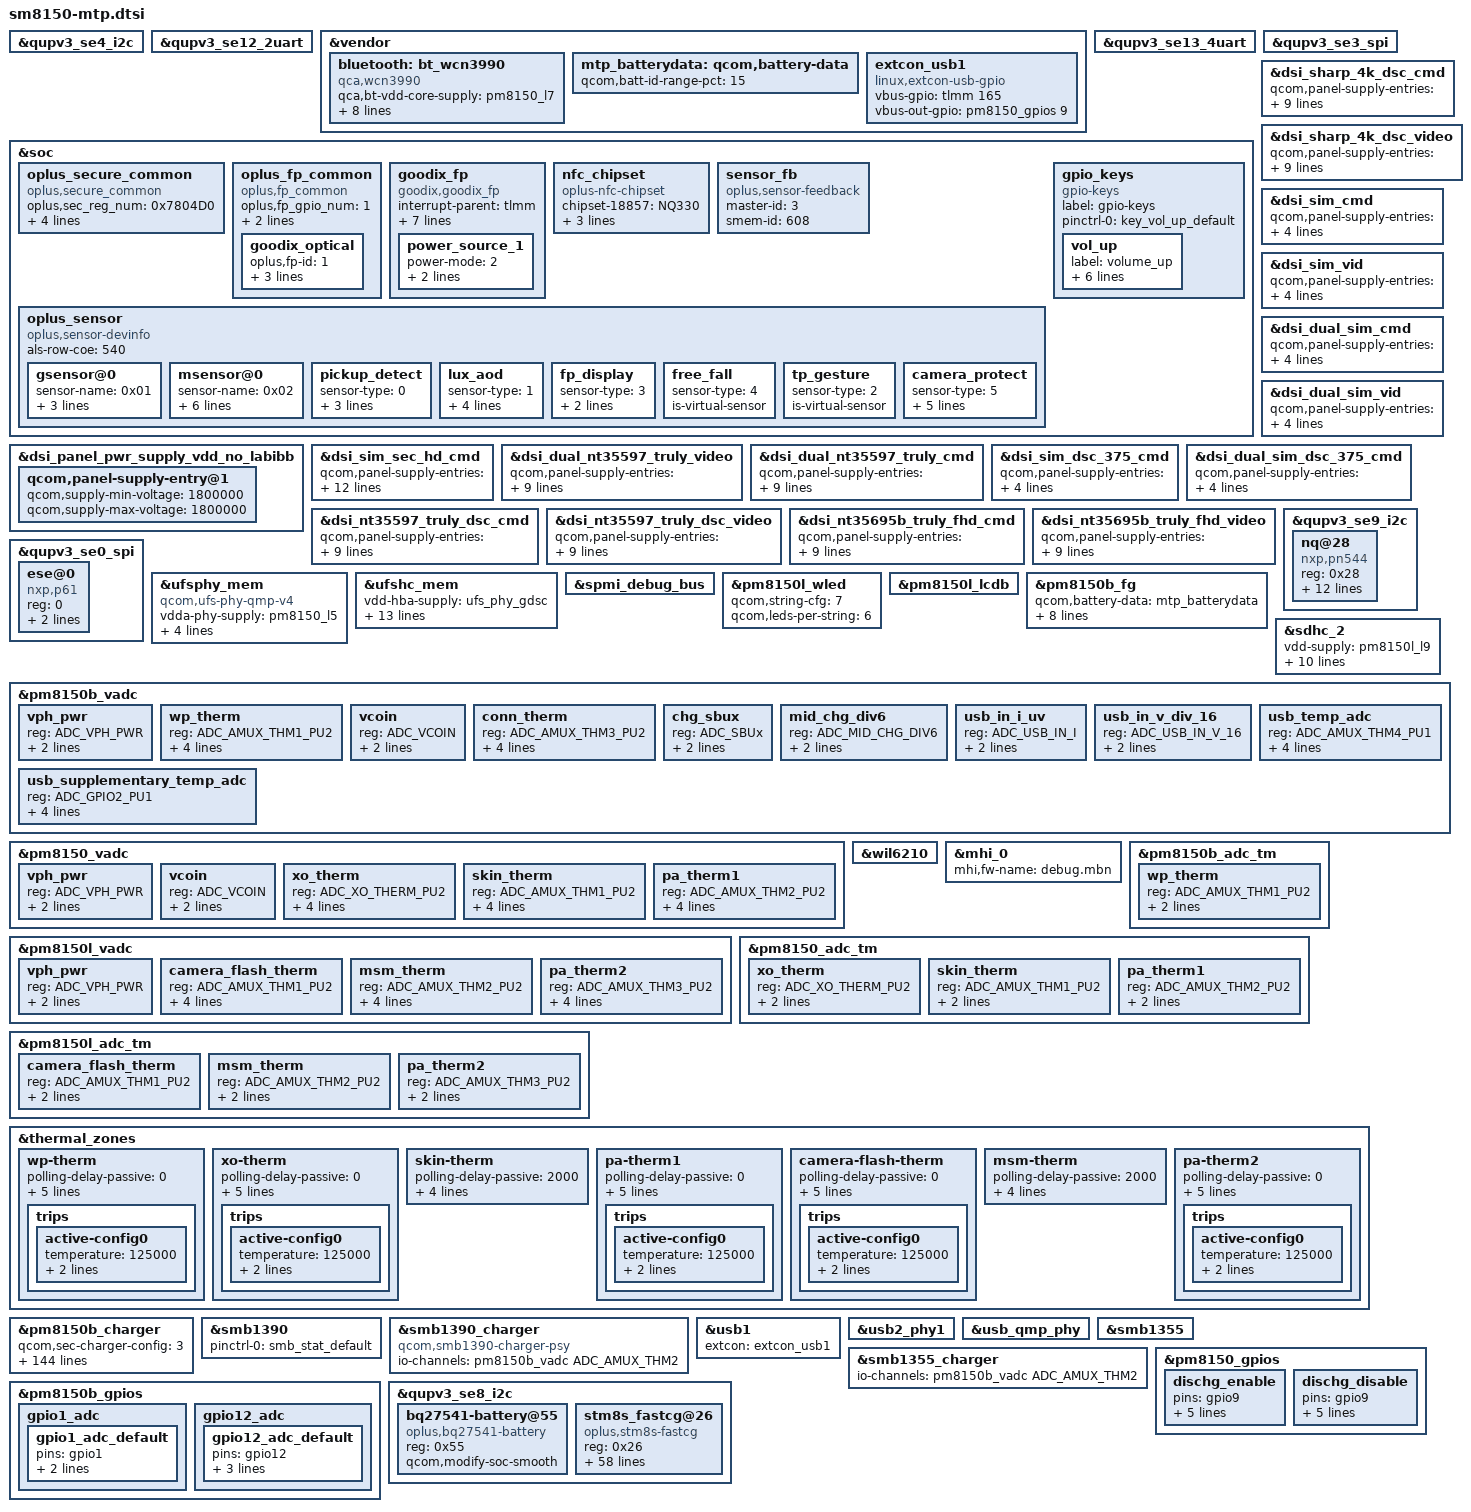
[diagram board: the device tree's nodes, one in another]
/* Copyright (c) 2017-2020, The Linux Foundation. All rights reserved.
 *
 * This program is free software; you can redistribute it and/or modify
 * it under the terms of the GNU General Public License version 2 and
 * only version 2 as published by the Free Software Foundation.
 *
 * This program is distributed in the hope that it will be useful,
 * but WITHOUT ANY WARRANTY; without even the implied warranty of
 * MERCHANTABILITY or FITNESS FOR A PARTICULAR PURPOSE.  See the
 * GNU General Public License for more details.
 */

#include <dt-bindings/gpio/gpio.h>
#include <dt-bindings/input/input.h>

#include "sm8150-pmic-overlay.dtsi"
#include "sm8150-sde-display.dtsi"
#include "sm8150-camera-sensor-mtp.dtsi"
#include "sm8150-thermal-overlay.dtsi"

&qupv3_se4_i2c {
#address-cells = <1>;
#size-cells = <0>;

#include "smb1390.dtsi"
#include "smb1355.dtsi"
};

&qupv3_se12_2uart {
	status = "ok";
};

&vendor {
	bluetooth: bt_wcn3990 {
		compatible = "qca,wcn3990";
		qca,bt-vdd-core-supply = <&pm8150_l7>;
		qca,bt-vdd-pa-supply = <&pm8150l_l2>;
		qca,bt-vdd-ldo-supply = <&pm8150l_l11>;

		qca,bt-vdd-core-voltage-level = <1800000 1800000>;
		qca,bt-vdd-pa-voltage-level = <1304000 1304000>;
		qca,bt-vdd-ldo-voltage-level = <3312000 3312000>;

		qca,bt-vdd-core-current-level = <0>; /* LPM/PFM */
		qca,bt-vdd-pa-current-level = <0>; /* LPM/PFM */
		qca,bt-vdd-ldo-current-level = <0>; /* LPM/PFM */
	};

	mtp_batterydata: qcom,battery-data {
		qcom,batt-id-range-pct = <15>;
		#include "fg-gen4-batterydata-alium-3600mah.dtsi"
	};

	extcon_usb1: extcon_usb1 {
		compatible = "linux,extcon-usb-gpio";
		/*pm8150_gpios 10 is for step motor, use the dummy gpio 165 for driver probe */
		vbus-gpio = <&tlmm 165 GPIO_ACTIVE_HIGH>;
                /*#ifdef OPLUS_FEATURE_FINGERPRINT*/
                //modify by Long.Liu 20190101, for fingerprint power gpio
		//id-gpio = <&tlmm 101 GPIO_ACTIVE_HIGH>;
                /*#endif*/
		vbus-out-gpio = <&pm8150_gpios 9 GPIO_ACTIVE_HIGH>;

		pinctrl-names = "default";
		/*#ifdef OPLUS_FEATURE_FINGERPRINT*/
		//modify by Long.Liu 20190101, for fingerprint power gpio
		//pinctrl-0 = <&usb2_vbus_det_default
		//	     &usb2_id_det_default
		//	     &usb2_vbus_boost_default>;
		/*#endif*/
	};
};

&qupv3_se13_4uart {
	status = "ok";
};

&qupv3_se3_spi {
	status = "ok";
};

&qupv3_se4_i2c {
	status = "ok";
};

&soc {


	/* #ifdef OPLUS_FEATURE_SECURITY_COMMON */
	oplus_secure_common {
		compatible = "oplus,secure_common";
		oplus,sec_reg_num = <0x7804D0>;
		oplus,sec_en_anti_reg = <0x78019C>;
		oplus,sec_override1_reg = <0x7860C0>;
		oplus,override1_en_value = <0x1>;
		oplus,cryptokey_unsupport_status = <0x1>;
	};
	/* #endif OPLUS_FEATURE_SECURITY_COMMON */

	/* #ifdef OPLUS_FEATURE_FINGERPRINT */
	oplus_fp_common {
        compatible = "oplus,fp_common";
        oplus,fp_gpio_num = <1>;
        oplus,fp_gpio_0 = <&tlmm 90 0x0>;
        pinctrl-names = "default";
        pinctrl-0 = <&gpio_id2_default>;
        goodix_optical {
            oplus,fp-id = <1>; /* fp id mapping table */
            vendor-chip = <11>; /* please refer to the struct fp_vendor_t in oplus_fp_commmon.n */
            eng-menu = "-1,-1"; /* represents SNR, inclination test item in engineer menu, and 0/1 means off/on */
            chip-name = "G_OPTICAL_18857_G2_4";  /* /proc/fp_id, will be displayed in engineer menu  */
        };
	};

	goodix_fp {
		status = "ok";
		compatible = "goodix,goodix_fp";
		interrupt-parent = <&tlmm>;
		interrupts = <118 0>;
		power-mode = <2> ; /*please refer to the struct fp_power_mode_t in oplus_fp_commmon.h ,0: power mode not set, 1: ldo power, 2: gpio power, 3: auto power */
		goodix,gpio_irq = <&tlmm 118 0x1>;
		goodix,gpio_reset = <&tlmm 131 0x0>;
		goodix,goodix_pwr = <&tlmm 101 0x0>;
		//ldo5-supply = <&pm660l_l5>;  // pm660l_l5 for goodix_fp
		pinctrl-names = "default";
			pinctrl-0 = <&gpio_goodix_irq_default>;
			power-num = <1>;
			power_source_1 {
					power-mode = <2>;
					power-name = "goodix,goodix_pwr";
					delay-time = <0>;
			};
		};
	//#endif /*OPLUS_FEATURE_FINGERPRINT*/

	//#ifdef OPLUS_FEATURE_BRINGUP
	nfc_chipset {
		compatible = "oplus-nfc-chipset";
		chipset-18857 = "NQ330";
		chipset-18855 = "NQ330";
		chipset-18853 = "NQ330";
		chipset-18851 = "NQ330";
	};
	//#endif OPLUS_FEATURE_BRINGUP

	//#ifdef OPLUS_FEATURE_SENSOR_SMEM
	/*enum sensor_id { OPLUS_ACCEL,OPLUS_GYRO,OPLUS_MAG,OPLUS_LIGHT,OPLUS_PROXIMITY,OPLUS_SAR,OPLUS_CT,OPLUS_BAROMETER,SENSORS_NUM};*/
        sensor_fb: sensor_fb {
            compatible = "oplus,sensor-feedback";
            master-id  = <3>;
            smem-id    = <608>;
        };
	oplus_sensor {
		compatible = "oplus,sensor-devinfo";
		als-row-coe = <540>;
		/*enum {LSM6DSM = 0x01, BMI160 = 0x02, LSM6DS3 = 0x04};*/
		gsensor@0 {
			sensor-name = <0x01>;//LSM6DSM
			sensor-direction = <3>;
			sensor-index = <0>;//source num
			sensor-type = <0>;//OPLUS_ACCEL
		};
		/* enum {AKM0991X = 0x01, MMC5603 = 0x02};*/
		msensor@0 {
			sensor-name = <0x02>;//MMC5603
			sensor-direction = <4>;
			sensor-index = <0>;
			sensor-type = <2>;//OPLUS_MAG
			parameter-number= <18>;
			//sensor-parameter = <2>;//0-useless;other- to differ special parameter
			soft-mag-parameter = <9964 0 37 0 845 1 169 1 10676 0 312 1 145 1 249 0 11758 0>;//e00 sign e01 sign ...
		};
		/*virtual sensor
		enum sensor_algo_id {
			OPLUS_PICKUP_DETECT,
			OPLUS_LUX_AOD,
			OPLUS_TP_GESTURE,
			OPLUS_FP_DISPLAY,
			OPLUS_FREE_FALL,
			OPLUS_CAMERA_PROTECT,
			SENSOR_ALGO_NUM
		}*/
		pickup_detect {
			sensor-type = <0>;//OPLUS_PICKUP_DETECT
			is-virtual-sensor;
			is-need-prox = <0>;//0 - disable; 1 - enable
			prox-type = <0>;//prox_type: 0 - proximity; 1 - proximity_fake
		};
		lux_aod {
			sensor-type = <1>; //OPLUS_LUX_AOD
			is-virtual-sensor;
			thrd-low = <12>;
			thrd-high = <50>;
			als-type = <1>; // 1 - wise_light; 0 - ambient_light
		};
		fp_display {
			sensor-type = <3>; //OPLUS_FP_DISPLAY
			is-virtual-sensor;
			prox-type = <0>; // 0 - proximity; 1 - proximity_fake
		};
		free_fall {
			sensor-type = <4>; //OPLUS_FREE_FALL
			is-virtual-sensor;
		};
		tp_gesture {
			sensor-type = <2>; //OPLUS_TP_GESTURE
			is-virtual-sensor;
		};
		camera_protect {
			sensor-type = <5>; //OPLUS_CAMERA_PROTECT
			is-virtual-sensor;
			layout_offset_x = <270>;
			layout_offset_y = <361>;
			init_pin = <163>;
			is_chip_pin = <1>;
		};
	};
	//#endif /*OPLUS_FEATURE_SENSOR_SMEM*/
	gpio_keys {
		compatible = "gpio-keys";
		label = "gpio-keys";

		pinctrl-names = "default";
		pinctrl-0 = <&key_vol_up_default>;

		vol_up {
			label = "volume_up";
			gpios = <&pm8150_gpios 6 GPIO_ACTIVE_LOW>;
			linux,input-type = <1>;
			linux,code = <KEY_VOLUMEUP>;
			gpio-key,wakeup;
			debounce-interval = <15>;
			linux,can-disable;
		};
	};

//#ifdef OPLUS_FEATURE_FINGERPRINT
//	qcomqbt1000:qcom,qbt1000 {
//		compatible = "qcom,qbt1000";
//		clock-names = "core", "iface";
//		clock-frequency = <25000000>;
//		qcom,ipc-gpio = <&tlmm 118 0>;
//		pinctrl-names = "default";
//		pinctrl-0 = <&key_home_default>;
//		qcom,finger-detect-gpio = <&pm8150_gpios 1 0>;
//	};
//#endif
};

&dsi_panel_pwr_supply_vdd_no_labibb {
	qcom,panel-supply-entry@1 {
		qcom,supply-min-voltage = <1800000>;
		qcom,supply-max-voltage = <1800000>;
	};
};

&dsi_sharp_4k_dsc_cmd {
	qcom,panel-supply-entries = <&dsi_panel_pwr_supply>;
	qcom,mdss-dsi-bl-pmic-control-type = "bl_ctrl_wled";
	qcom,mdss-dsi-bl-min-level = <1>;
	qcom,mdss-dsi-bl-max-level = <4095>;
	qcom,mdss-dsi-mode-sel-gpio-state = "dual_port";
	qcom,panel-mode-gpio = <&tlmm 7 0>;
	qcom,platform-te-gpio = <&tlmm 8 0>;
	qcom,platform-reset-gpio = <&tlmm 6 0>;
};

&dsi_sharp_4k_dsc_video {
	qcom,panel-supply-entries = <&dsi_panel_pwr_supply>;
	qcom,mdss-dsi-bl-pmic-control-type = "bl_ctrl_wled";
	qcom,mdss-dsi-bl-min-level = <1>;
	qcom,mdss-dsi-bl-max-level = <4095>;
	qcom,mdss-dsi-mode-sel-gpio-state = "dual_port";
	qcom,panel-mode-gpio = <&tlmm 7 0>;
	qcom,platform-te-gpio = <&tlmm 8 0>;
	qcom,platform-reset-gpio = <&tlmm 6 0>;
};

&dsi_sim_cmd {
	qcom,panel-supply-entries = <&dsi_panel_pwr_supply>;
	qcom,mdss-dsi-bl-pmic-control-type = "bl_ctrl_dcs";
	qcom,platform-reset-gpio = <&tlmm 6 0>;
};

&dsi_sim_vid {
	qcom,panel-supply-entries = <&dsi_panel_pwr_supply>;
	qcom,mdss-dsi-bl-pmic-control-type = "bl_ctrl_dcs";
	qcom,platform-reset-gpio = <&tlmm 6 0>;
};

&dsi_dual_sim_cmd {
	qcom,panel-supply-entries = <&dsi_panel_pwr_supply>;
	qcom,mdss-dsi-bl-pmic-control-type = "bl_ctrl_dcs";
	qcom,platform-reset-gpio = <&tlmm 6 0>;
};

&dsi_dual_sim_vid {
	qcom,panel-supply-entries = <&dsi_panel_pwr_supply>;
	qcom,mdss-dsi-bl-pmic-control-type = "bl_ctrl_dcs";
	qcom,platform-reset-gpio = <&tlmm 6 0>;
};

&dsi_sim_sec_hd_cmd {
	qcom,panel-supply-entries = <&dsi_panel_pwr_supply>;
	qcom,panel-sec-supply-entries = <&dsi_panel_pwr_supply_vdd_no_labibb>;
	qcom,mdss-dsi-bl-pmic-control-type = "bl_ctrl_wled";
	qcom,mdss-dsi-bl-min-level = <1>;
	qcom,mdss-dsi-bl-max-level = <4095>;
	qcom,mdss-dsi-mode-sel-gpio-state = "single_port";
	qcom,panel-mode-gpio = <&tlmm 7 0>;
	qcom,platform-reset-gpio = <&tlmm 6 0>;
	qcom,panel-sec-mode-gpio = <&tlmm 77 0>;
	qcom,platform-sec-reset-gpio = <&tlmm 66 0>;
};

&dsi_dual_nt35597_truly_video {
	qcom,panel-supply-entries = <&dsi_panel_pwr_supply>;
	qcom,mdss-dsi-bl-pmic-control-type = "bl_ctrl_wled";
	qcom,mdss-dsi-bl-min-level = <1>;
	qcom,mdss-dsi-bl-max-level = <4095>;
	qcom,mdss-dsi-mode-sel-gpio-state = "dual_port";
	qcom,panel-mode-gpio = <&tlmm 7 0>;
	qcom,platform-te-gpio = <&tlmm 8 0>;
	qcom,platform-reset-gpio = <&tlmm 6 0>;
};

&dsi_dual_nt35597_truly_cmd {
	qcom,panel-supply-entries = <&dsi_panel_pwr_supply>;
	qcom,mdss-dsi-bl-pmic-control-type = "bl_ctrl_wled";
	qcom,mdss-dsi-bl-min-level = <1>;
	qcom,mdss-dsi-bl-max-level = <4095>;
	qcom,mdss-dsi-mode-sel-gpio-state = "dual_port";
	qcom,panel-mode-gpio = <&tlmm 7 0>;
	qcom,platform-te-gpio = <&tlmm 8 0>;
	qcom,platform-reset-gpio = <&tlmm 6 0>;
};

&dsi_sim_dsc_375_cmd {
	qcom,panel-supply-entries = <&dsi_panel_pwr_supply>;
	qcom,mdss-dsi-bl-pmic-control-type = "bl_ctrl_dcs";
	qcom,platform-reset-gpio = <&tlmm 6 0>;
};

&dsi_dual_sim_dsc_375_cmd {
	qcom,panel-supply-entries = <&dsi_panel_pwr_supply>;
	qcom,mdss-dsi-bl-pmic-control-type = "bl_ctrl_dcs";
	qcom,platform-reset-gpio = <&tlmm 6 0>;
};

&dsi_nt35597_truly_dsc_cmd {
	qcom,panel-supply-entries = <&dsi_panel_pwr_supply>;
	qcom,mdss-dsi-bl-pmic-control-type = "bl_ctrl_wled";
	qcom,mdss-dsi-bl-min-level = <1>;
	qcom,mdss-dsi-bl-max-level = <4095>;
	qcom,mdss-dsi-mode-sel-gpio-state = "single_port";
	qcom,panel-mode-gpio = <&tlmm 7 0>;
	qcom,platform-te-gpio = <&tlmm 8 0>;
	qcom,platform-reset-gpio = <&tlmm 6 0>;
};

&dsi_nt35597_truly_dsc_video {
	qcom,panel-supply-entries = <&dsi_panel_pwr_supply>;
	qcom,mdss-dsi-bl-pmic-control-type = "bl_ctrl_wled";
	qcom,mdss-dsi-bl-min-level = <1>;
	qcom,mdss-dsi-bl-max-level = <4095>;
	qcom,mdss-dsi-mode-sel-gpio-state = "single_port";
	qcom,panel-mode-gpio = <&tlmm 7 0>;
	qcom,platform-te-gpio = <&tlmm 8 0>;
	qcom,platform-reset-gpio = <&tlmm 6 0>;
};

&dsi_nt35695b_truly_fhd_cmd {
	qcom,panel-supply-entries = <&dsi_panel_pwr_supply>;
	qcom,mdss-dsi-bl-pmic-control-type = "bl_ctrl_wled";
	qcom,mdss-dsi-bl-min-level = <1>;
	qcom,mdss-dsi-bl-max-level = <4095>;
	qcom,mdss-dsi-mode-sel-gpio-state = "single_port";
	qcom,panel-mode-gpio = <&tlmm 7 0>;
	qcom,platform-te-gpio = <&tlmm 8 0>;
	qcom,platform-reset-gpio = <&tlmm 6 0>;
};

&dsi_nt35695b_truly_fhd_video {
	qcom,panel-supply-entries = <&dsi_panel_pwr_supply>;
	qcom,mdss-dsi-bl-pmic-control-type = "bl_ctrl_wled";
	qcom,mdss-dsi-bl-min-level = <1>;
	qcom,mdss-dsi-bl-max-level = <4095>;
	qcom,mdss-dsi-mode-sel-gpio-state = "single_port";
	qcom,panel-mode-gpio = <&tlmm 7 0>;
	qcom,platform-te-gpio = <&tlmm 8 0>;
	qcom,platform-reset-gpio = <&tlmm 6 0>;
};

//#ifdef OPLUS_BUG_STABILITY
/*&qupv3_se9_i2c {
	status = "ok";

	#address-cells = <1>;
	#size-cells = <0>;

	nq@28 {
		compatible = "qcom,nq-nci";
		reg = <0x28>;
		qcom,nq-irq = <&tlmm 47 0x00>;
		qcom,nq-ven = <&tlmm 41 0x00>;
		qcom,nq-firm = <&tlmm 48 0x00>;
		qcom,nq-clkreq = <&tlmm 113 0x00>;
		qcom,nq-esepwr = <&tlmm 42 0x00>;
		interrupt-parent = <&tlmm>;
		interrupts = <47 0>;
		interrupt-names = "nfc_irq";
		pinctrl-names = "nfc_active", "nfc_suspend";
		pinctrl-0 = <&nfc_int_active &nfc_enable_active
					&nfc_clk_req_active>;
		pinctrl-1 = <&nfc_int_suspend &nfc_enable_suspend
					&nfc_clk_req_suspend>;
	};
};*/

&qupv3_se9_i2c {
	status = "ok";
	nq@28 {
		compatible = "nxp,pn544";
		reg = <0x28>;
		nxp,pn544-irq = <&tlmm 47 0x00>;
		nxp,pn544-ven = <&tlmm 41 0x00>;
		nxp,pn544-fw-dwnld = <&tlmm 48 0x00>;
		nxp,pn544-clk-gpio = <&tlmm 113 0x00>;
		nxp,pn544-ese-pwr = <&tlmm 49 0x00>;
		interrupt-parent = <&tlmm>;
		qcom,clk-src = "BBCLK3";
		interrupts = <47 0>;
		interrupt-names = "nfc_irq";
		pinctrl-names = "nfc_active", "nfc_suspend";
		pinctrl-0 = <&nfc_int_active &nfc_enable_active
					&nfc_clk_req_active>;
		pinctrl-1 = <&nfc_int_suspend &nfc_enable_suspend
					&nfc_clk_req_suspend>;
	};
};

&qupv3_se0_spi {
    status = "ok";

    ese@0 {
        compatible = "nxp,p61";
        reg = <0>;
        spi-max-frequency = <8000000>;
	nxp,nfcc = "4-0028";
    };
};
//#endif OPLUS_BUG_STABILITY

&ufsphy_mem {
	compatible = "qcom,ufs-phy-qmp-v4";

	vdda-phy-supply = <&pm8150_l5>;
	vdda-phy-always-on;
	vdda-pll-supply = <&pm8150l_l3>;
	vdda-phy-max-microamp = <90200>;
	vdda-pll-max-microamp = <19000>;

	status = "ok";
};

&ufshc_mem {
	vdd-hba-supply = <&ufs_phy_gdsc>;
	vdd-hba-fixed-regulator;
	vcc-supply = <&pm8150_l10>;
	vcc-voltage-level = <2504000 2950000>;
	vcc-low-voltage-sup;
	vccq-supply = <&pm8150_l9>;
	vccq2-supply = <&pm8150_s4>;
	vcc-max-microamp = <750000>;
	vccq-max-microamp = <700000>;
	vccq2-max-microamp = <750000>;

	qcom,vddp-ref-clk-supply = <&pm8150_l9>;
	qcom,vddp-ref-clk-max-microamp = <100>;
	qcom,vccq-parent-supply = <&pm8150l_s8>;
	qcom,vccq-parent-max-microamp = <210000>;

	status = "ok";
};

&spmi_debug_bus {
	status = "ok";
};

&pm8150l_wled {
	qcom,string-cfg= <7>;
	qcom,leds-per-string = <6>;
	status = "ok";
};

&pm8150l_lcdb {
	status = "ok";
};

&pm8150b_fg {
	qcom,battery-data = <&mtp_batterydata>;
	qcom,hold-soc-while-full;
	qcom,linearize-soc;
	qcom,five-pin-battery;
	qcom,cl-wt-enable;
	/* ESR fast calibration */
	qcom,fg-esr-timer-chg-fast = <0 7>;
	qcom,fg-esr-timer-dischg-fast = <0 7>;
	qcom,fg-esr-timer-chg-slow = <0 96>;
	qcom,fg-esr-timer-dischg-slow = <0 96>;
	/*op disable ers calibration*/
	/*qcom,fg-esr-cal-soc-thresh = <26 230>;*/
	/*qcom,fg-esr-cal-temp-thresh = <10 40>;*/
};

&sdhc_2 {
	vdd-supply = <&pm8150l_l9>;
	qcom,vdd-voltage-level = <2950000 2960000>;
	qcom,vdd-current-level = <200 800000>;

	vdd-io-supply = <&pm8150l_l6>;
	qcom,vdd-io-voltage-level = <1808000 2960000>;
	qcom,vdd-io-current-level = <200 22000>;

	pinctrl-names = "active", "sleep";
	pinctrl-0 = <&sdc2_clk_on  &sdc2_cmd_on &sdc2_data_on &storage_cd>;
	pinctrl-1 = <&sdc2_clk_off &sdc2_cmd_off &sdc2_data_off &storage_cd>;

	cd-gpios = <&tlmm 96 GPIO_ACTIVE_LOW>;

	status = "ok";
};

&pm8150b_vadc {
	vph_pwr {
		reg = <ADC_VPH_PWR>;
		label = "vph_pwr";
		qcom,pre-scaling = <1 3>;
	};

	wp_therm {
		reg = <ADC_AMUX_THM1_PU2>;
		label = "wp_therm";
		qcom,ratiometric;
		qcom,hw-settle-time = <200>;
		qcom,pre-scaling = <1 1>;
	};

	vcoin {
		reg = <ADC_VCOIN>;
		label = "vcoin";
		qcom,pre-scaling = <1 3>;
	};

	conn_therm {
		reg = <ADC_AMUX_THM3_PU2>;
		label = "conn_therm";
		qcom,ratiometric;
		qcom,hw-settle-time = <200>;
		qcom,pre-scaling = <1 1>;
	};

	chg_sbux {
		reg = <ADC_SBUx>;
		label = "chg_sbux";
		qcom,pre-scaling = <1 3>;
	};

	mid_chg_div6 {
		reg = <ADC_MID_CHG_DIV6>;
		label = "chg_mid";
		qcom,pre-scaling = <1 6>;
	};

	usb_in_i_uv {
		reg = <ADC_USB_IN_I>;
		label = "usb_in_i_uv";
		qcom,pre-scaling = <1 1>;
	};

	usb_in_v_div_16 {
		reg = <ADC_USB_IN_V_16>;
		label = "usb_in_v_div_16";
		qcom,pre-scaling = <1 16>;
	};
        usb_temp_adc {
                reg = <ADC_AMUX_THM4_PU1>;
                label = "usb_temp_adc";
                qcom,pre-scaling = <1 1>;
                qcom,ratiometric;
                qcom,hw-settle-time = <800>;
        };
        usb_supplementary_temp_adc {
                reg = <ADC_GPIO2_PU1>;
                label = "usb_supplementary_temp_adc";
                qcom,pre-scaling = <1 1>;
                qcom,ratiometric;
                qcom,hw-settle-time = <200>;
        };
};

&pm8150_vadc {
	vph_pwr {
		reg = <ADC_VPH_PWR>;
		label = "vph_pwr";
		qcom,pre-scaling = <1 3>;
	};

	vcoin {
		reg = <ADC_VCOIN>;
		label = "vcoin";
		qcom,pre-scaling = <1 3>;
	};

	xo_therm {
		reg = <ADC_XO_THERM_PU2>;
		label = "xo_therm";
		qcom,ratiometric;
		qcom,hw-settle-time = <200>;
		qcom,pre-scaling = <1 1>;
	};

	skin_therm {
		reg = <ADC_AMUX_THM1_PU2>;
		label = "skin_therm";
		qcom,ratiometric;
		qcom,hw-settle-time = <200>;
		qcom,pre-scaling = <1 1>;
	};

	pa_therm1 {
		reg = <ADC_AMUX_THM2_PU2>;
		label = "pa_therm1";
		qcom,ratiometric;
		qcom,hw-settle-time = <200>;
		qcom,pre-scaling = <1 1>;
	};
};

&pm8150l_vadc {
	vph_pwr {
		reg = <ADC_VPH_PWR>;
		label = "vph_pwr";
		qcom,pre-scaling = <1 3>;
	};

	camera_flash_therm {
		reg = <ADC_AMUX_THM1_PU2>;
		label = "camera_flash_therm";
		qcom,ratiometric;
		qcom,hw-settle-time = <200>;
		qcom,pre-scaling = <1 1>;
	};

	msm_therm {
		reg = <ADC_AMUX_THM2_PU2>;
		label = "msm_therm";
		qcom,ratiometric;
		qcom,hw-settle-time = <200>;
		qcom,pre-scaling = <1 1>;
	};

	pa_therm2 {
		reg = <ADC_AMUX_THM3_PU2>;
		label = "pa_therm2";
		qcom,ratiometric;
		qcom,hw-settle-time = <200>;
		qcom,pre-scaling = <1 1>;
	};
};

&wil6210 {
	status = "ok";
};

&mhi_0 {
	mhi,fw-name = "debug.mbn";
};

&pm8150b_adc_tm {
	wp_therm {
		reg = <ADC_AMUX_THM1_PU2>;
		qcom,ratiometric;
		qcom,hw-settle-time = <200>;
	};
};

&pm8150_adc_tm {
	xo_therm {
		reg = <ADC_XO_THERM_PU2>;
		qcom,ratiometric;
		qcom,hw-settle-time = <200>;
	};

	skin_therm {
		reg = <ADC_AMUX_THM1_PU2>;
		qcom,ratiometric;
		qcom,hw-settle-time = <200>;
	};

	pa_therm1 {
		reg = <ADC_AMUX_THM2_PU2>;
		qcom,ratiometric;
		qcom,hw-settle-time = <200>;
	};
};

&pm8150l_adc_tm {
	camera_flash_therm {
		reg = <ADC_AMUX_THM1_PU2>;
		qcom,ratiometric;
		qcom,hw-settle-time = <200>;
	};

	msm_therm {
		reg = <ADC_AMUX_THM2_PU2>;
		qcom,ratiometric;
		qcom,hw-settle-time = <200>;
	};

	pa_therm2 {
		reg = <ADC_AMUX_THM3_PU2>;
		qcom,ratiometric;
		qcom,hw-settle-time = <200>;
	};
};

&thermal_zones {
	wp-therm {
		polling-delay-passive = <0>;
		polling-delay = <0>;
		thermal-governor = "user_space";
		thermal-sensors = <&pm8150b_adc_tm ADC_AMUX_THM1_PU2>;
		wake-capable-sensor;
		trips {
			active-config0 {
				temperature = <125000>;
				hysteresis = <1000>;
				type = "passive";
			};
		};
	};

	xo-therm {
		polling-delay-passive = <0>;
		polling-delay = <0>;
		thermal-governor = "user_space";
		thermal-sensors = <&pm8150_adc_tm ADC_XO_THERM_PU2>;
		wake-capable-sensor;
		trips {
			active-config0 {
				temperature = <125000>;
				hysteresis = <1000>;
				type = "passive";
			};
		};
	};

	skin-therm {
		polling-delay-passive = <2000>;
		polling-delay = <0>;
		thermal-governor = "step_wise";
		thermal-sensors = <&pm8150_adc_tm ADC_AMUX_THM1_PU2>;
	};

	pa-therm1 {
		polling-delay-passive = <0>;
		polling-delay = <0>;
		thermal-governor = "user_space";
		thermal-sensors = <&pm8150_adc_tm ADC_AMUX_THM2_PU2>;
		wake-capable-sensor;
		trips {
			active-config0 {
				temperature = <125000>;
				hysteresis = <1000>;
				type = "passive";
			};
		};
	};

	camera-flash-therm {
		polling-delay-passive = <0>;
		polling-delay = <0>;
		thermal-governor = "user_space";
		thermal-sensors = <&pm8150l_adc_tm ADC_AMUX_THM1_PU2>;
		wake-capable-sensor;
		trips {
			active-config0 {
				temperature = <125000>;
				hysteresis = <1000>;
				type = "passive";
			};
		};
	};

	msm-therm {
		polling-delay-passive = <2000>;
		polling-delay = <0>;
		thermal-governor = "step_wise";
		thermal-sensors = <&pm8150l_adc_tm ADC_AMUX_THM2_PU2>;
	};

	pa-therm2 {
		polling-delay-passive = <0>;
		polling-delay = <0>;
		thermal-governor = "user_space";
		thermal-sensors = <&pm8150l_adc_tm ADC_AMUX_THM3_PU2>;
		wake-capable-sensor;
		trips {
			active-config0 {
				temperature = <125000>;
				hysteresis = <1000>;
				type = "passive";
			};
		};
	};
};

&pm8150b_charger {
	qcom,sec-charger-config = <3>;
	qcom,auto-recharge-soc = <98>;
	io-channels = <&pm8150b_vadc ADC_MID_CHG_DIV6>,
		      <&pm8150b_vadc ADC_USB_IN_I>,
		      <&pm8150b_vadc ADC_SBUx>,
		      <&pm8150b_vadc ADC_VPH_PWR>,
		      <&pm8150b_vadc ADC_CHG_TEMP>,
		      <&pm8150b_vadc ADC_USB_IN_V_16>,
                      <&pm8150b_vadc ADC_AMUX_THM4_PU1>,
                      <&pm8150b_vadc ADC_GPIO2_PU1>,
                      <&pm8150_vadc ADC_AMUX_THM1_PU2>;
	io-channel-names = "mid_voltage",
			   "usb_in_current",
			   "sbux_res",
			   "vph_voltage",
			   "chg_temp",
			   "usb_in_voltage",
                           "usb_temp_adc",
                           "usb_supplementary_temp_adc",
                           "skin_therm";
	qcom,battery-data = <&mtp_batterydata>;
	qcom,step-charging-enable;
	//qcom,sw-jeita-enable;
	qcom,wd-bark-time-secs = <16>;
	qcom,suspend-input-on-debug-batt;
        op,low-voltage-charger;
};

&smb1390 {
	pinctrl-names = "default";
	pinctrl-0 = <&smb_stat_default>;
	status = "ok";
};

&smb1390_charger {
	/delete-property/ compatible;
	compatible = "qcom,smb1390-charger-psy";
	io-channels = <&pm8150b_vadc ADC_AMUX_THM2>;
	io-channel-names = "cp_die_temp";
	status = "ok";
};

&usb1 {
	extcon = <&extcon_usb1>;
	status = "ok";
};

&usb2_phy1 {
	status = "ok";
};

&usb_qmp_phy {
	status = "ok";
};

&smb1355 {
	status = "ok";
};

&smb1355_charger {
	io-channels = <&pm8150b_vadc ADC_AMUX_THM2>;
	io-channel-names = "charger_temp";
	status = "ok";
};

&pm8150b_gpios {
    gpio1_adc {
        gpio1_adc_default: gpio1_adc_default {
        pins = "gpio1"; /* GPIO 1 */
        function = "normal"; /* normal */
        bias-high-impedance; /* DISABLE GPIO1 for ADC*/
        };
    };

    gpio12_adc {
        gpio12_adc_default: gpio12_adc_default {
        pins = "gpio12"; /* GPIO 12 */
        function = "normal"; /* normal */
        bias-pull-up;
        bias-high-impedance; /* DISABLE GPIO12 for ADC*/
        };
    };

};
&pm8150_gpios {
        dischg_enable: dischg_enable {
                pins = "gpio9"; /* GPIO 9 */
                function = "normal"; /* normal */
                bias-disable; //No Pull
                power-source = <0>;//VIN0 3.3
                output-high; //digital output, no invert
                qcom,drive-strength = <3>; //LOW strength
                //drive-push-pull;//CMOS
        };

        dischg_disable: dischg_disable {
                pins = "gpio9"; /* GPIO 9 */
                function = "normal"; /* normal */
                bias-disable; //No Pull
                power-source = <0>;//VIN0 3.3
                output-low; //digital output, no invert
                qcom,drive-strength = <3>; //LOW strength
                //drive-push-pull;//CMOS
        };
};

&pm8150b_charger {

                        //for smb5:
                        qcom,usb-icl-ua = <1800000>;
                        qcom,fcc-max-ua = <3000000>;
                        //qcom,fv-max-uv = <4365000>;
                        qcom,hvdcp-disable;
                        //io-channels = <&pm8150b_vadc ADC_GPIO3>;
                        //io-channel-names = "chgID_voltage_adc";
                        qcom,otg-cl-ua = <1500000>;
                        qcom,float-option = <1>;
                        qcom,oplus-pps-usbpd-detection = <&pm8150b_pdphy>;

                        //for oplus chg framework:
                        qcom,input_current_charger_ma = <2000>;
                        qcom,input_current_usb_ma = <500>;
                        qcom,input_current_cdp_ma = <1500>;
                        qcom,input_current_led_ma = <1200>;
                        qcom,input_current_led_ma_high = <1200>;
                        qcom,input_current_led_ma_warm = <1500>;
                        qcom,input_current_led_ma_normal = <2000>;
			qcom,pd_input_current_charger_ma = <3000>;

                        qcom,input_current_camera_ma = <1200>;
                        //qcom,input_current_led_ma_overtemp = <900>;
                        qcom,overtemp_bat_decidegc = <350>;
                        qcom,iterm_disabled = <0>;
                        qcom,iterm_ma = <310>;
                        qcom,recharge-mv = <100>;
                        qcom,batt_capacity_mah = <3700>;/*typical capacity*/
                        //qcom,batt_capacity_mah = <3950>; /*rated capacity*/

                        qcom,removed_bat_decidegc = <190>;  /*<-19C*/

                        qcom,cold_bat_decidegc = <20>;  /*-2C~0C*/
                        qcom,temp_cold_vfloat_mv = <3975>;
                        qcom,temp_cold_fastchg_current_ma = <320>;

                        qcom,little_cold_bat_decidegc = <0>;    /*0C~5C*/
                        qcom,temp_little_cold_vfloat_mv = <4390>;
                        qcom,temp_little_cold_fastchg_current_ma_high = <1450>;
                        qcom,temp_little_cold_fastchg_current_ma_low = <1450>;
                        qcom,temp_little_cold_fastchg_current_ma = <1450>;
			qcom,pd_temp_little_cold_fastchg_current_ma_high = <1450>;
			qcom,pd_temp_little_cold_fastchg_current_ma_low = <1450>;

                        qcom,cool_bat_decidegc = <50>;  /*5C~12C*/
                        qcom,temp_cool_vfloat_mv = <4390>;
                        qcom,temp_cool_fastchg_current_ma_high = <2100>;
                        qcom,temp_cool_fastchg_current_ma_low = <2100>;
			qcom,pd_temp_cool_fastchg_current_ma_high = <2100>;
			qcom,pd_temp_cool_fastchg_current_ma_low = <2100>;

                        qcom,little_cool_bat_decidegc = <120>;  /*12C~16C*/
                        qcom,temp_little_cool_vfloat_mv = <4390>;
                        qcom,temp_little_cool_fastchg_current_ma = <2100>;
			qcom,pd_temp_little_cool_fastchg_current_ma = <2100>;

                        qcom,normal_bat_decidegc = <160>;       /*16C~45C*/
                        qcom,temp_normal_fastchg_current_ma = <3000>;
			qcom,pd_temp_normal_fastchg_current_ma = <3000>;
                        qcom,temp_normal_vfloat_mv = <4390>;

                        qcom,warm_bat_decidegc = <450>;         /*45C~53C*/ /*8pin Bat Vooc project need add 3 degree C*/
                        qcom,temp_warm_vfloat_mv = <4130>;
                        qcom,temp_warm_fastchg_current_ma = <1050>;
			qcom,pd_temp_warm_fastchg_current_ma = <1050>;

                        qcom,hot_bat_decidegc = <500>;

                        qcom,non_standard_vfloat_mv = <3980>;
                        qcom,non_standard_fastchg_current_ma = <512>;

                        qcom,short_c_bat_cv_mv = <4330>;
                        qcom,short_c_bat_vfloat_mv = <3800>;
                        qcom,short_c_bat_fastchg_current_ma = <512>;

			qcom,cold_vfloat_sw_limit = <3675>;
                        qcom,little_cold_vfloat_sw_limit = <4150>;
                        qcom,cool_vfloat_sw_limit = <4150>;
                        qcom,little_cool_vfloat_sw_limit = <4270>;
                        qcom,normal_vfloat_sw_limit = <4270>;
                        qcom,warm_vfloat_sw_limit = <3980>;
			qcom,non_standard_vfloat_sw_limit = <3930>;
                        qcom,short_c_bat_vfloat_sw_limit = <3750>;

                        qcom,max_chg_time_sec = <36000>;
                        qcom,charger_hv_thr = <5700>;
                        qcom,charger_recv_thr = <5500>;
                        qcom,charger_lv_thr = <3400>;
                        qcom,vbatt_full_thr = <4400>;
                        qcom,vbatt_hv_thr = <4500>;
                        qcom,vfloat_step_mv = <8>;
                        qcom,non_standard_vfloat_over_sw_limit = <3990>;
                        qcom,cold_vfloat_over_sw_limit = <3990>;
                        qcom,little_cold_vfloat_over_sw_limit = <4445>;
                        qcom,cool_vfloat_over_sw_limit = <4445>;
                        qcom,little_cool_vfloat_over_sw_limit = <4445>;
                        qcom,normal_vfloat_over_sw_limit = <4445>;
                        qcom,warm_vfloat_over_sw_limit = <4140>;

                        qcom,vbatt_power_off = <3300>;
                        qcom,vbatt_soc_1 = <3410>;
                        qcom,vooc_project = <1>;
                        qcom,vbatt_num = <1>;
                        qcom,ffc_support;

                        qcom,normal_vterm_hw_inc = <18>;
                        qcom,non_normal_vterm_hw_inc = <18>;

                        qcom,ff1_normal_fastchg_ma = <1000>;
                        qcom,ffc2_normal_fastchg_ma = <650>;/*12C~35c*/
                        qcom,ffc2_temp_warm_decidegc = <350>;
                        qcom,ffc2_warm_fastchg_ma = <750>;/*35C~40c*/
                        qcom,ffc2_temp_high_decidegc = <400>;
                        qcom,ffc2_temp_low_decidegc = <160>;
                        qcom,ffc2_exit_step_ma = <170>;

                        qcom,ffc_normal_vfloat_sw_limit = <4430>;
                        qcom,ffc_temp_normal_vfloat_mv = <4550>;
                        qcom,ffc_normal_vfloat_over_sw_limit = <4550>;

                        qcom,default_iterm_ma = <310>;
                        qcom,default_temp_normal_fastchg_current_ma = <3000>;
                        qcom,default_normal_vfloat_sw_limit = <4385>;
                        qcom,default_temp_normal_vfloat_mv = <4390>;
                        qcom,default_normal_vfloat_over_sw_limit = <4445>;

                        qcom,default_temp_little_cool_fastchg_current_ma = <2100>;
                        qcom,default_little_cool_vfloat_sw_limit = <4385>;
                        qcom,default_temp_little_cool_vfloat_mv = <4390>;
                        qcom,default_little_cool_vfloat_over_sw_limit = <4445>;

                        //qcom,offset_temp = <30>;
                        //for control:
                        //qcom,suspend_after_full;
                        qcom,check_batt_full_by_sw;
                        qcom,external_gauge;
                        qcom,chg_ctrl_by_lcd;
                        qcom,chg_ctrl_by_camera;
                        qcom,sw_vfloat_over_protect_enable;

                        qcom,support_abnormal_adapter;

                       // qcom,chargerid_switch-gpio = <&tlmm 94 0x00>;
                        qcom,ship-gpio = <&tlmm 21 0x00>;
                        qcom,ccdetect-gpio = <&tlmm 91 0x00>;
                        //qcom,shortc-gpio = <&tlmm 43 0x00>;
                        qcom,dischg-gpio = <&pm8150_gpios 9 0x00>;

                        pinctrl-names = "ship_active", "ship_sleep",
                                        "ccdetect_active", "ccdetect_sleep",
                                        "dischg_enable", "dischg_disable",
                                        "gpio1_adc_default", "gpio12_adc_default";

                        pinctrl-0 = <&ship_active>;
                        pinctrl-1 = <&ship_sleep>;
                        pinctrl-2 = <&ccdetect_active>;
                        pinctrl-3 = <&ccdetect_sleep>;
                        pinctrl-4 = <&dischg_enable>;
                        pinctrl-5 = <&dischg_disable>;
                        pinctrl-6 = <&gpio1_adc_default>;
                        pinctrl-7 = <&gpio12_adc_default>;

};
&qupv3_se8_i2c {
        status = "okay";

        bq27541-battery@55 {
                status = "okay";
                compatible = "oplus,bq27541-battery";
                reg = <0x55>;
                qcom,modify-soc-smooth;
        };

        stm8s_fastcg@26{
                status = "okay";
                compatible = "oplus,stm8s-fastcg";
                reg = <0x26>;
                qcom,vooc-low-temp = <120>;
                qcom,oplus_batt_4400mv;
                qcom,vooc_fw_update_newmethod;
		qcom,vooc_reply_mcu_bits = <3>;
                //qcom,vooc-fw-type = <0x22>; //5A
                qcom,vooc-high-temp = <430>;
                qcom,vooc-low-soc = <1>;
                qcom,vooc-high-soc = <85>;
                qcom,vooc-fw-type = <10>;

                qcom,vooc_multistep_adjust_current_support;
                qcom,vooc_multistep_initial_batt_temp = <310>;
                qcom,vooc_strategy_normal_current = <0x06>;
                qcom,vooc-normal-to-little-cool-current = <0x05>;
                qcom,vooc_batt_over_high_temp = <440>;
                qcom,vooc_batt_over_low_temp = <45>;
                qcom,vooc_over_high_or_low_current = <0x0>;

                qcom,vooc_strategy1_batt_high_temp0 = <425>;
                qcom,vooc_strategy1_batt_high_temp1 = <430>;
                qcom,vooc_strategy1_batt_high_temp2 = <435>;
                qcom,vooc_strategy1_batt_low_temp2 = <420>;
                qcom,vooc_strategy1_batt_low_temp1 = <415>;
                qcom,vooc_strategy1_batt_low_temp0 = <400>;

                qcom,vooc_strategy1_high_current0 = <0x04>;//4A
                qcom,vooc_strategy1_high_current1 = <0x03>;//3A
                qcom,vooc_strategy1_high_current2 = <0x02>;//2A
                qcom,vooc_strategy1_low_current2 = <0x03>;//3A
                qcom,vooc_strategy1_low_current1 = <0x04>;//4A
                qcom,vooc_strategy1_low_current0 = <0x04>;//4A

                qcom,vooc_strategy2_batt_up_temp1 = <375>;
                qcom,vooc_strategy2_batt_up_down_temp2 = <380>;
                qcom,vooc_strategy2_batt_up_temp3 = <390>;
                qcom,vooc_strategy2_batt_up_down_temp4 = <400>;
                qcom,vooc_strategy2_batt_up_temp5 = <410>;
                qcom,vooc_strategy2_batt_up_temp6 = <415>;
                qcom,vooc_strategy2_high0_current = <0x05>;
                qcom,vooc_strategy2_high1_current = <0x04>;
                qcom,vooc_strategy2_high2_current = <0x03>;
                qcom,vooc_strategy2_high3_current = <0x02>;

		/* skin thermal temp adjust the dash current */
		qcom,skin-thermal-high-threshold = <370>;
		qcom,skin-thermal-normal-threshold = <340>;

                qcom,abnormal_adapter_current = <0x00 0x00 0x09 0x09 0x07 0x07 0x05 0x05 0x03 0x03>;

                pinctrl-names = "switch1_act_switch2_act", "switch1_sleep_switch2_sleep",
                                "switch1_act_switch3_act", "switch1_sleep_switch3_sleep",
                                "switch1_act_switch2_sleep", "switch1_sleep_switch2_act",
                                "clock_active","clock_sleep",
                                "data_active","data_sleep",
                                "reset_active","reset_sleep";
                pinctrl-0 = <&charging_switch1_active>;
                pinctrl-1 = <&charging_switch1_sleep >;
                pinctrl-2 = <&charging_switch1_active>;
                pinctrl-3 = <&charging_switch1_sleep >;
                pinctrl-4 = <&charging_switch1_active>;
                pinctrl-5 = <&charging_switch1_sleep>;
                pinctrl-6 = <&charging_clock_active >;
                pinctrl-7 = <&charging_clock_sleep >;
                pinctrl-8 = <&charging_data_active >;
                pinctrl-9 = <&charging_data_sleep >;
                pinctrl-10 = <&charging_reset_active >;
                pinctrl-11 = <&charging_reset_sleep >;

                qcom,charging_switch1-gpio = <&tlmm 94 0x00>;
		qcom,charging_switch1_ctr1-gpio = <&tlmm 59 0x00>;
                //qcom,charging_switch2-gpio = <&tlmm 59 0x00>;
                //qcom,charging_switch3-gpio = <&tlmm 38 0x00>;

                qcom,charging_reset-gpio = <&tlmm 10 0x00>;
                qcom,charging_clock-gpio = <&tlmm 92 0x00>;
                qcom,charging_data-gpio = <&tlmm 93 0x00>;
        };
};
